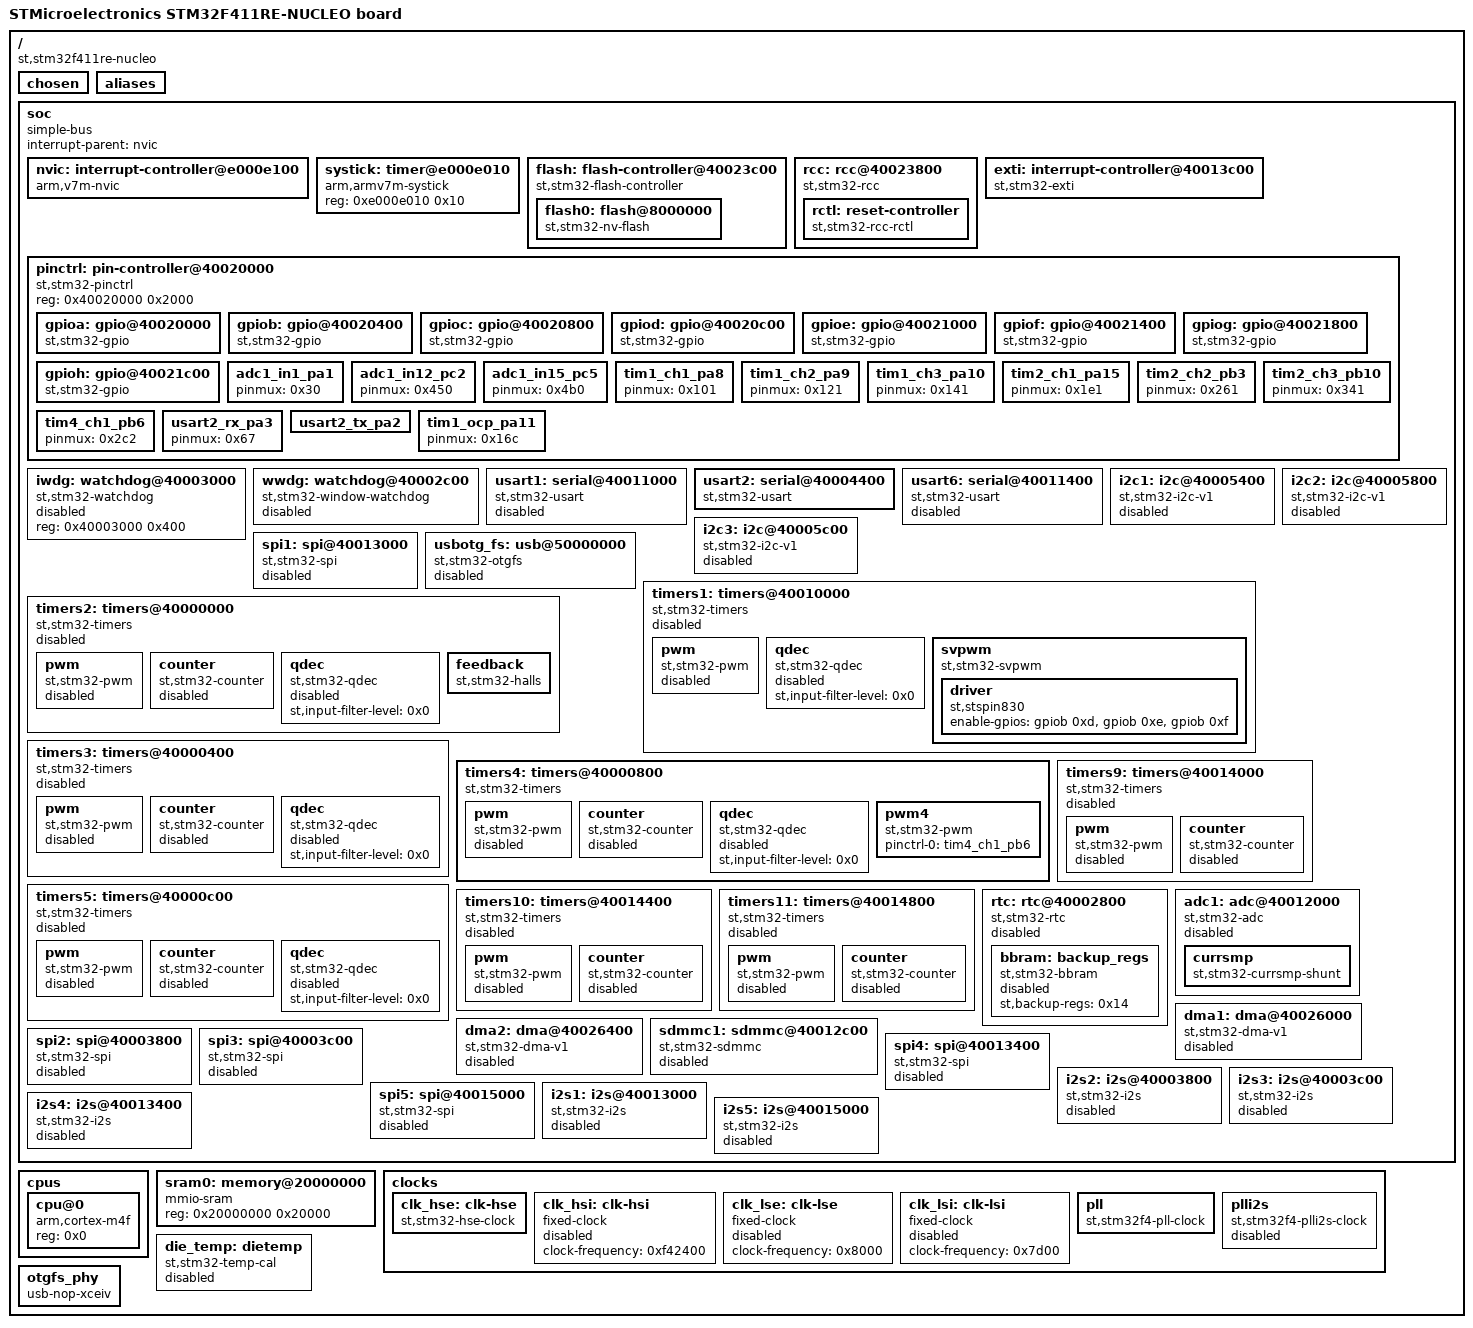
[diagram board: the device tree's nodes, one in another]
/dts-v1/;

/ {
	#address-cells = < 0x1 >;
	#size-cells = < 0x1 >;
	model = "STMicroelectronics STM32F411RE-NUCLEO board";
	compatible = "st,stm32f411re-nucleo";
	chosen {
		zephyr,flash-controller = &flash;
		zephyr,console = &usart2;
		zephyr,shell-uart = &usart2;
		zephyr,sram = &sram0;
		zephyr,flash = &flash0;
	};
	aliases {
	};
	soc {
		#address-cells = < 0x1 >;
		#size-cells = < 0x1 >;
		compatible = "simple-bus";
		interrupt-parent = < &nvic >;
		ranges;
		nvic: interrupt-controller@e000e100 {
			#address-cells = < 0x1 >;
			compatible = "arm,v7m-nvic";
			reg = < 0xe000e100 0xc00 >;
			interrupt-controller;
			#interrupt-cells = < 0x2 >;
			arm,num-irq-priority-bits = < 0x4 >;
			phandle = < 0x1 >;
		};
		systick: timer@e000e010 {
			compatible = "arm,armv7m-systick";
			reg = < 0xe000e010 0x10 >;
		};
		flash: flash-controller@40023c00 {
			compatible = "st,stm32-flash-controller", "st,stm32f4-flash-controller";
			reg = < 0x40023c00 0x400 >;
			interrupts = < 0x4 0x0 >;
			#address-cells = < 0x1 >;
			#size-cells = < 0x1 >;
			flash0: flash@8000000 {
				compatible = "st,stm32-nv-flash", "soc-nv-flash";
				write-block-size = < 0x1 >;
				max-erase-time = < 0xfa0 >;
				reg = < 0x8000000 0x80000 >;
			};
		};
		rcc: rcc@40023800 {
			compatible = "st,stm32-rcc";
			#clock-cells = < 0x2 >;
			reg = < 0x40023800 0x400 >;
			clocks = < &pll >;
			clock-frequency = < 0x5b8d800 >;
			ahb-prescaler = < 0x1 >;
			apb1-prescaler = < 0x2 >;
			apb2-prescaler = < 0x1 >;
			phandle = < 0x3 >;
			rctl: reset-controller {
				compatible = "st,stm32-rcc-rctl";
				#reset-cells = < 0x1 >;
				phandle = < 0x4 >;
			};
		};
		exti: interrupt-controller@40013c00 {
			compatible = "st,stm32-exti";
			interrupt-controller;
			#interrupt-cells = < 0x1 >;
			reg = < 0x40013c00 0x400 >;
			num-lines = < 0x10 >;
			interrupts = < 0x6 0x0 >, < 0x7 0x0 >, < 0x8 0x0 >, < 0x9 0x0 >, < 0xa 0x0 >, < 0x17 0x0 >, < 0x28 0x0 >;
			interrupt-names = "line0", "line1", "line2", "line3", "line4", "line5-9", "line10-15";
			line-ranges = < 0x0 0x1 >, < 0x1 0x1 >, < 0x2 0x1 >, < 0x3 0x1 >, < 0x4 0x1 >, < 0x5 0x5 >, < 0xa 0x6 >;
		};
		pinctrl: pin-controller@40020000 {
			compatible = "st,stm32-pinctrl";
			#address-cells = < 0x1 >;
			#size-cells = < 0x1 >;
			reg = < 0x40020000 0x2000 >;
			gpioa: gpio@40020000 {
				compatible = "st,stm32-gpio";
				gpio-controller;
				#gpio-cells = < 0x2 >;
				reg = < 0x40020000 0x400 >;
				clocks = < &rcc 0x30 0x1 >;
				phandle = < 0x11 >;
			};
			gpiob: gpio@40020400 {
				compatible = "st,stm32-gpio";
				gpio-controller;
				#gpio-cells = < 0x2 >;
				reg = < 0x40020400 0x400 >;
				clocks = < &rcc 0x30 0x2 >;
				phandle = < 0xd >;
			};
			gpioc: gpio@40020800 {
				compatible = "st,stm32-gpio";
				gpio-controller;
				#gpio-cells = < 0x2 >;
				reg = < 0x40020800 0x400 >;
				clocks = < &rcc 0x30 0x4 >;
				status = "okay";
			};
			gpiod: gpio@40020c00 {
				compatible = "st,stm32-gpio";
				gpio-controller;
				#gpio-cells = < 0x2 >;
				reg = < 0x40020c00 0x400 >;
				clocks = < &rcc 0x30 0x8 >;
			};
			gpioe: gpio@40021000 {
				compatible = "st,stm32-gpio";
				gpio-controller;
				#gpio-cells = < 0x2 >;
				reg = < 0x40021000 0x400 >;
				clocks = < &rcc 0x30 0x10 >;
			};
			gpiof: gpio@40021400 {
				compatible = "st,stm32-gpio";
				gpio-controller;
				#gpio-cells = < 0x2 >;
				reg = < 0x40021400 0x400 >;
				clocks = < &rcc 0x30 0x20 >;
			};
			gpiog: gpio@40021800 {
				compatible = "st,stm32-gpio";
				gpio-controller;
				#gpio-cells = < 0x2 >;
				reg = < 0x40021800 0x400 >;
				clocks = < &rcc 0x30 0x40 >;
			};
			gpioh: gpio@40021c00 {
				compatible = "st,stm32-gpio";
				gpio-controller;
				#gpio-cells = < 0x2 >;
				reg = < 0x40021c00 0x400 >;
				clocks = < &rcc 0x30 0x80 >;
			};
			adc1_in1_pa1: adc1_in1_pa1 {
				pinmux = < 0x30 >;
				phandle = < 0x13 >;
			};
			adc1_in12_pc2: adc1_in12_pc2 {
				pinmux = < 0x450 >;
				phandle = < 0x14 >;
			};
			adc1_in15_pc5: adc1_in15_pc5 {
				pinmux = < 0x4b0 >;
				phandle = < 0x15 >;
			};
			tim1_ch1_pa8: tim1_ch1_pa8 {
				pinmux = < 0x101 >;
				phandle = < 0x8 >;
			};
			tim1_ch2_pa9: tim1_ch2_pa9 {
				pinmux = < 0x121 >;
				phandle = < 0x9 >;
			};
			tim1_ch3_pa10: tim1_ch3_pa10 {
				pinmux = < 0x141 >;
				phandle = < 0xa >;
			};
			tim2_ch1_pa15: tim2_ch1_pa15 {
				pinmux = < 0x1e1 >;
				phandle = < 0xe >;
			};
			tim2_ch2_pb3: tim2_ch2_pb3 {
				pinmux = < 0x261 >;
				phandle = < 0xf >;
			};
			tim2_ch3_pb10: tim2_ch3_pb10 {
				pinmux = < 0x341 >;
				phandle = < 0x10 >;
			};
			tim4_ch1_pb6: tim4_ch1_pb6 {
				pinmux = < 0x2c2 >;
				phandle = < 0x12 >;
			};
			usart2_rx_pa3: usart2_rx_pa3 {
				pinmux = < 0x67 >;
				phandle = < 0x6 >;
			};
			usart2_tx_pa2: usart2_tx_pa2 {
				pinmux = < 0x47 >;
				bias-pull-up;
				phandle = < 0x5 >;
			};
			tim1_ocp_pa11: tim1_ocp_pa11 {
				pinmux = < 0x16c >;
				phandle = < 0xb >;
			};
		};
		iwdg: watchdog@40003000 {
			compatible = "st,stm32-watchdog";
			reg = < 0x40003000 0x400 >;
			status = "disabled";
		};
		wwdg: watchdog@40002c00 {
			compatible = "st,stm32-window-watchdog";
			reg = < 0x40002c00 0x400 >;
			clocks = < &rcc 0x40 0x800 >;
			interrupts = < 0x0 0x7 >;
			status = "disabled";
		};
		usart1: serial@40011000 {
			compatible = "st,stm32-usart", "st,stm32-uart";
			reg = < 0x40011000 0x400 >;
			clocks = < &rcc 0x44 0x10 >;
			resets = < &rctl 0x484 >;
			interrupts = < 0x25 0x0 >;
			status = "disabled";
		};
		usart2: serial@40004400 {
			compatible = "st,stm32-usart", "st,stm32-uart";
			reg = < 0x40004400 0x400 >;
			clocks = < &rcc 0x40 0x20000 >;
			resets = < &rctl 0x411 >;
			interrupts = < 0x26 0x0 >;
			status = "okay";
			pinctrl-0 = < &usart2_tx_pa2 &usart2_rx_pa3 >;
			pinctrl-names = "default";
			current-speed = < 0x1c200 >;
		};
		usart6: serial@40011400 {
			compatible = "st,stm32-usart", "st,stm32-uart";
			reg = < 0x40011400 0x400 >;
			clocks = < &rcc 0x44 0x20 >;
			resets = < &rctl 0x485 >;
			interrupts = < 0x47 0x0 >;
			status = "disabled";
		};
		i2c1: i2c@40005400 {
			compatible = "st,stm32-i2c-v1";
			clock-frequency = < 0x186a0 >;
			#address-cells = < 0x1 >;
			#size-cells = < 0x0 >;
			reg = < 0x40005400 0x400 >;
			clocks = < &rcc 0x40 0x200000 >;
			interrupts = < 0x1f 0x0 >, < 0x20 0x0 >;
			interrupt-names = "event", "error";
			status = "disabled";
		};
		i2c2: i2c@40005800 {
			compatible = "st,stm32-i2c-v1";
			clock-frequency = < 0x186a0 >;
			#address-cells = < 0x1 >;
			#size-cells = < 0x0 >;
			reg = < 0x40005800 0x400 >;
			clocks = < &rcc 0x40 0x400000 >;
			interrupts = < 0x21 0x0 >, < 0x22 0x0 >;
			interrupt-names = "event", "error";
			status = "disabled";
		};
		i2c3: i2c@40005c00 {
			compatible = "st,stm32-i2c-v1";
			clock-frequency = < 0x186a0 >;
			#address-cells = < 0x1 >;
			#size-cells = < 0x0 >;
			reg = < 0x40005c00 0x400 >;
			clocks = < &rcc 0x40 0x800000 >;
			interrupts = < 0x48 0x0 >, < 0x49 0x0 >;
			interrupt-names = "event", "error";
			status = "disabled";
		};
		spi1: spi@40013000 {
			compatible = "st,stm32-spi";
			#address-cells = < 0x1 >;
			#size-cells = < 0x0 >;
			reg = < 0x40013000 0x400 >;
			clocks = < &rcc 0x44 0x1000 >;
			interrupts = < 0x23 0x5 >;
			status = "disabled";
		};
		usbotg_fs: usb@50000000 {
			compatible = "st,stm32-otgfs";
			reg = < 0x50000000 0x40000 >;
			interrupts = < 0x43 0x0 >;
			interrupt-names = "otgfs";
			num-bidir-endpoints = < 0x4 >;
			ram-size = < 0x500 >;
			maximum-speed = "full-speed";
			phys = < &otgfs_phy >;
			clocks = < &rcc 0x34 0x80 >, < &rcc 0x2 0xff >;
			status = "disabled";
		};
		timers1: timers@40010000 {
			compatible = "st,stm32-timers";
			reg = < 0x40010000 0x400 >;
			clocks = < &rcc 0x44 0x1 >;
			resets = < &rctl 0x480 >;
			interrupts = < 0x18 0x0 >, < 0x19 0x0 >, < 0x1a 0x0 >, < 0x1b 0x0 >;
			interrupt-names = "brk", "up", "trgcom", "cc";
			st,prescaler = < 0x0 >;
			status = "disabled";
			pwm {
				compatible = "st,stm32-pwm";
				status = "disabled";
				#pwm-cells = < 0x3 >;
			};
			qdec {
				compatible = "st,stm32-qdec";
				status = "disabled";
				st,input-filter-level = < 0x0 >;
			};
			svpwm: svpwm {
				compatible = "st,stm32-svpwm";
				status = "okay";
				pinctrl-0 = < &tim1_ch1_pa8 &tim1_ch2_pa9 &tim1_ch3_pa10 &tim1_ocp_pa11 >;
				pinctrl-names = "default";
				currsmp = < &currsmp >;
				driver {
					compatible = "st,stspin830";
					enable-gpios = < &gpiob 0xd 0x0 >, < &gpiob 0xe 0x0 >, < &gpiob 0xf 0x0 >;
				};
			};
		};
		timers2: timers@40000000 {
			compatible = "st,stm32-timers";
			reg = < 0x40000000 0x400 >;
			clocks = < &rcc 0x40 0x1 >;
			resets = < &rctl 0x400 >;
			interrupts = < 0x1c 0x0 >;
			interrupt-names = "global";
			st,prescaler = < 0x0 >;
			status = "disabled";
			pwm {
				compatible = "st,stm32-pwm";
				status = "disabled";
				#pwm-cells = < 0x3 >;
			};
			counter {
				compatible = "st,stm32-counter";
				status = "disabled";
			};
			qdec {
				compatible = "st,stm32-qdec";
				status = "disabled";
				st,input-filter-level = < 0x0 >;
			};
			feedback: feedback {
				compatible = "st,stm32-halls";
				pinctrl-0 = < &tim2_ch1_pa15 &tim2_ch2_pb3 &tim2_ch3_pb10 >;
				pinctrl-names = "default";
				h1-gpios = < &gpioa 0xf 0x0 >;
				h2-gpios = < &gpiob 0x3 0x0 >;
				h3-gpios = < &gpiob 0xa 0x0 >;
				phase-shift = < 0x3c >;
			};
		};
		timers3: timers@40000400 {
			compatible = "st,stm32-timers";
			reg = < 0x40000400 0x400 >;
			clocks = < &rcc 0x40 0x2 >;
			resets = < &rctl 0x401 >;
			interrupts = < 0x1d 0x0 >;
			interrupt-names = "global";
			st,prescaler = < 0x0 >;
			status = "disabled";
			pwm {
				compatible = "st,stm32-pwm";
				status = "disabled";
				#pwm-cells = < 0x3 >;
			};
			counter {
				compatible = "st,stm32-counter";
				status = "disabled";
			};
			qdec {
				compatible = "st,stm32-qdec";
				status = "disabled";
				st,input-filter-level = < 0x0 >;
			};
		};
		timers4: timers@40000800 {
			compatible = "st,stm32-timers";
			reg = < 0x40000800 0x400 >;
			clocks = < &rcc 0x40 0x4 >;
			resets = < &rctl 0x402 >;
			interrupts = < 0x1e 0x0 >;
			interrupt-names = "global";
			st,prescaler = < 0xa >;
			status = "okay";
			pwm {
				compatible = "st,stm32-pwm";
				status = "disabled";
				#pwm-cells = < 0x3 >;
			};
			counter {
				compatible = "st,stm32-counter";
				status = "disabled";
			};
			qdec {
				compatible = "st,stm32-qdec";
				status = "disabled";
				st,input-filter-level = < 0x0 >;
			};
			pwm4: pwm4 {
				compatible = "st,stm32-pwm";
				status = "okay";
				pinctrl-0 = < &tim4_ch1_pb6 >;
				pinctrl-names = "default";
				#pwm-cells = < 0x3 >;
			};
		};
		timers5: timers@40000c00 {
			compatible = "st,stm32-timers";
			reg = < 0x40000c00 0x400 >;
			clocks = < &rcc 0x40 0x8 >;
			resets = < &rctl 0x403 >;
			interrupts = < 0x32 0x0 >;
			interrupt-names = "global";
			st,prescaler = < 0x0 >;
			status = "disabled";
			pwm {
				compatible = "st,stm32-pwm";
				status = "disabled";
				#pwm-cells = < 0x3 >;
			};
			counter {
				compatible = "st,stm32-counter";
				status = "disabled";
			};
			qdec {
				compatible = "st,stm32-qdec";
				status = "disabled";
				st,input-filter-level = < 0x0 >;
			};
		};
		timers9: timers@40014000 {
			compatible = "st,stm32-timers";
			reg = < 0x40014000 0x400 >;
			clocks = < &rcc 0x44 0x10000 >;
			resets = < &rctl 0x490 >;
			interrupts = < 0x18 0x0 >;
			interrupt-names = "global";
			st,prescaler = < 0x0 >;
			status = "disabled";
			pwm {
				compatible = "st,stm32-pwm";
				status = "disabled";
				#pwm-cells = < 0x3 >;
			};
			counter {
				compatible = "st,stm32-counter";
				status = "disabled";
			};
		};
		timers10: timers@40014400 {
			compatible = "st,stm32-timers";
			reg = < 0x40014400 0x400 >;
			clocks = < &rcc 0x44 0x20000 >;
			resets = < &rctl 0x491 >;
			interrupts = < 0x19 0x0 >;
			interrupt-names = "global";
			st,prescaler = < 0x0 >;
			status = "disabled";
			pwm {
				compatible = "st,stm32-pwm";
				status = "disabled";
				#pwm-cells = < 0x3 >;
			};
			counter {
				compatible = "st,stm32-counter";
				status = "disabled";
			};
		};
		timers11: timers@40014800 {
			compatible = "st,stm32-timers";
			reg = < 0x40014800 0x400 >;
			clocks = < &rcc 0x44 0x40000 >;
			resets = < &rctl 0x492 >;
			interrupts = < 0x1a 0x0 >;
			interrupt-names = "global";
			st,prescaler = < 0x0 >;
			status = "disabled";
			pwm {
				compatible = "st,stm32-pwm";
				status = "disabled";
				#pwm-cells = < 0x3 >;
			};
			counter {
				compatible = "st,stm32-counter";
				status = "disabled";
			};
		};
		rtc: rtc@40002800 {
			compatible = "st,stm32-rtc";
			reg = < 0x40002800 0x400 >;
			interrupts = < 0x29 0x0 >;
			clocks = < &rcc 0x40 0x10000000 >;
			prescaler = < 0x8000 >;
			status = "disabled";
			bbram: backup_regs {
				compatible = "st,stm32-bbram";
				st,backup-regs = < 0x14 >;
				status = "disabled";
			};
		};
		adc1: adc@40012000 {
			compatible = "st,stm32-adc";
			reg = < 0x40012000 0x400 >;
			clocks = < &rcc 0x44 0x100 >;
			interrupts = < 0x12 0x0 >;
			status = "disabled";
			#io-channel-cells = < 0x1 >;
			temp-channel = < 0x12 >;
			vref-channel = < 0x11 >;
			phandle = < 0x19 >;
			currsmp: currsmp {
				compatible = "st,stm32-currsmp-shunt";
				pinctrl-0 = < &adc1_in1_pa1 &adc1_in12_pc2 &adc1_in15_pc5 >;
				pinctrl-names = "default";
				adc-resolution = < 0xc >;
				adc-tsample = < 0x3 >;
				adc-channels = < 0x1 0xc 0xf >;
				adc-trigger = < 0x10000 >;
				phandle = < 0xc >;
			};
		};
		dma1: dma@40026000 {
			compatible = "st,stm32-dma-v1";
			#dma-cells = < 0x4 >;
			reg = < 0x40026000 0x400 >;
			interrupts = < 0xb 0x0 0xc 0x0 0xd 0x0 0xe 0x0 0xf 0x0 0x10 0x0 0x11 0x0 0x2f 0x0 >;
			clocks = < &rcc 0x30 0x200000 >;
			status = "disabled";
			phandle = < 0x16 >;
		};
		dma2: dma@40026400 {
			compatible = "st,stm32-dma-v1";
			#dma-cells = < 0x4 >;
			reg = < 0x40026400 0x400 >;
			interrupts = < 0x38 0x0 0x39 0x0 0x3a 0x0 0x3b 0x0 0x3c 0x0 0x44 0x0 0x45 0x0 0x46 0x0 >;
			clocks = < &rcc 0x30 0x400000 >;
			st,mem2mem;
			status = "disabled";
			phandle = < 0x17 >;
		};
		sdmmc1: sdmmc@40012c00 {
			compatible = "st,stm32-sdmmc";
			reg = < 0x40012c00 0x400 >;
			clocks = < &rcc 0x44 0x800 >, < &rcc 0x2 0xff >;
			resets = < &rctl 0x48b >;
			interrupts = < 0x31 0x0 >;
			status = "disabled";
		};
		spi2: spi@40003800 {
			compatible = "st,stm32-spi";
			#address-cells = < 0x1 >;
			#size-cells = < 0x0 >;
			reg = < 0x40003800 0x400 >;
			clocks = < &rcc 0x40 0x4000 >;
			interrupts = < 0x24 0x5 >;
			status = "disabled";
		};
		spi3: spi@40003c00 {
			compatible = "st,stm32-spi";
			#address-cells = < 0x1 >;
			#size-cells = < 0x0 >;
			reg = < 0x40003c00 0x400 >;
			clocks = < &rcc 0x40 0x8000 >;
			interrupts = < 0x33 0x5 >;
			status = "disabled";
		};
		spi4: spi@40013400 {
			compatible = "st,stm32-spi";
			#address-cells = < 0x1 >;
			#size-cells = < 0x0 >;
			reg = < 0x40013400 0x400 >;
			clocks = < &rcc 0x44 0x2000 >;
			interrupts = < 0x54 0x5 >;
			status = "disabled";
		};
		i2s2: i2s@40003800 {
			compatible = "st,stm32-i2s";
			#address-cells = < 0x1 >;
			#size-cells = < 0x0 >;
			reg = < 0x40003800 0x400 >;
			clocks = < &rcc 0x40 0x4000 >;
			interrupts = < 0x24 0x5 >;
			dmas = < &dma1 0x4 0x0 0x400 0x3 &dma1 0x3 0x0 0x400 0x3 >;
			dma-names = "tx", "rx";
			status = "disabled";
		};
		i2s3: i2s@40003c00 {
			compatible = "st,stm32-i2s";
			#address-cells = < 0x1 >;
			#size-cells = < 0x0 >;
			reg = < 0x40003c00 0x400 >;
			clocks = < &rcc 0x40 0x8000 >;
			interrupts = < 0x33 0x5 >;
			dmas = < &dma1 0x5 0x0 0x400 0x3 &dma1 0x0 0x0 0x400 0x3 >;
			dma-names = "tx", "rx";
			status = "disabled";
		};
		spi5: spi@40015000 {
			compatible = "st,stm32-spi";
			#address-cells = < 0x1 >;
			#size-cells = < 0x0 >;
			reg = < 0x40015000 0x400 >;
			clocks = < &rcc 0x44 0x100000 >;
			interrupts = < 0x55 0x5 >;
			status = "disabled";
		};
		i2s1: i2s@40013000 {
			compatible = "st,stm32-i2s";
			#address-cells = < 0x1 >;
			#size-cells = < 0x0 >;
			reg = < 0x40013000 0x400 >;
			clocks = < &rcc 0x44 0x1000 >;
			interrupts = < 0x23 0x5 >;
			dmas = < &dma2 0x3 0x3 0x400 0x3 &dma2 0x2 0x3 0x400 0x3 >;
			dma-names = "tx", "rx";
			status = "disabled";
		};
		i2s4: i2s@40013400 {
			compatible = "st,stm32-i2s";
			#address-cells = < 0x1 >;
			#size-cells = < 0x0 >;
			reg = < 0x40013400 0x400 >;
			clocks = < &rcc 0x44 0x2000 >;
			interrupts = < 0x54 0x5 >;
			dmas = < &dma2 0x1 0x4 0x400 0x3 &dma2 0x0 0x4 0x400 0x3 >;
			dma-names = "tx", "rx";
			status = "disabled";
		};
		i2s5: i2s@40015000 {
			compatible = "st,stm32-i2s";
			#address-cells = < 0x1 >;
			#size-cells = < 0x0 >;
			reg = < 0x40015000 0x400 >;
			clocks = < &rcc 0x44 0x100000 >;
			interrupts = < 0x55 0x5 >;
			dmas = < &dma2 0x6 0x7 0x400 0x3 &dma2 0x5 0x7 0x400 0x3 >;
			dma-names = "tx", "rx";
			status = "disabled";
		};
	};
	cpus {
		#address-cells = < 0x1 >;
		#size-cells = < 0x0 >;
		cpu@0 {
			device_type = "cpu";
			compatible = "arm,cortex-m4f";
			reg = < 0x0 >;
		};
	};
	sram0: memory@20000000 {
		compatible = "mmio-sram";
		reg = < 0x20000000 0x20000 >;
	};
	clocks {
		clk_hse: clk-hse {
			#clock-cells = < 0x0 >;
			compatible = "st,stm32-hse-clock";
			status = "okay";
			hse-bypass;
			clock-frequency = < 0x7a1200 >;
			phandle = < 0x18 >;
		};
		clk_hsi: clk-hsi {
			#clock-cells = < 0x0 >;
			compatible = "fixed-clock";
			clock-frequency = < 0xf42400 >;
			status = "disabled";
		};
		clk_lse: clk-lse {
			#clock-cells = < 0x0 >;
			compatible = "fixed-clock";
			clock-frequency = < 0x8000 >;
			status = "disabled";
		};
		clk_lsi: clk-lsi {
			#clock-cells = < 0x0 >;
			compatible = "fixed-clock";
			clock-frequency = < 0x7d00 >;
			status = "disabled";
		};
		pll: pll {
			#clock-cells = < 0x0 >;
			compatible = "st,stm32f4-pll-clock";
			status = "okay";
			div-m = < 0x8 >;
			mul-n = < 0x180 >;
			div-p = < 0x4 >;
			div-q = < 0x8 >;
			clocks = < &clk_hse >;
			phandle = < 0x2 >;
		};
		plli2s: plli2s {
			#clock-cells = < 0x0 >;
			compatible = "st,stm32f4-plli2s-clock";
			status = "disabled";
		};
	};
	die_temp: dietemp {
		compatible = "st,stm32-temp-cal";
		ts-cal1-addr = < 0x1fff7a2c >;
		ts-cal2-addr = < 0x1fff7a2e >;
		ts-cal1-temp = < 0x1e >;
		ts-cal2-temp = < 0x6e >;
		ts-cal-vrefanalog = < 0xce4 >;
		io-channels = < &adc1 0x12 >;
		status = "disabled";
	};
	otgfs_phy: otgfs_phy {
		compatible = "usb-nop-xceiv";
		#phy-cells = < 0x0 >;
		phandle = < 0x7 >;
	};
};
